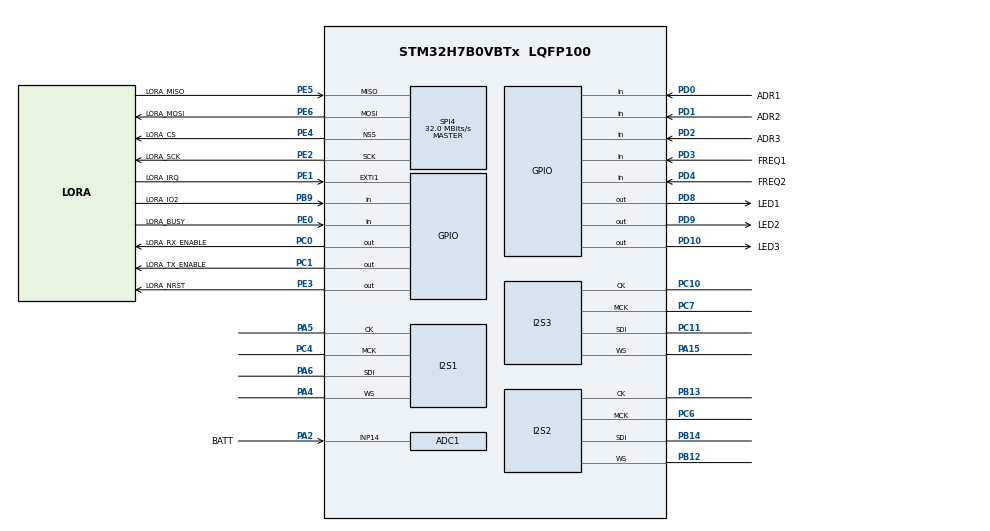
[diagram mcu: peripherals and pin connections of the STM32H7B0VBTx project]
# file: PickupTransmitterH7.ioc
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ADC1.Channel-0\#ChannelRegularConversion=ADC_CHANNEL_14
ADC1.NbrOfConversionFlag=1
ADC1.OffsetNumber-0\#ChannelRegularConversion=ADC_OFFSET_NONE
ADC1.OffsetSignedSaturation-0\#ChannelRegularConversion=DISABLE
ADC1.Rank-0\#ChannelRegularConversion=1
ADC1.SamplingTime-0\#ChannelRegularConversion=ADC_SAMPLETIME_1CYCLE_5
ADC1.master=1
CORTEX_M7.default_mode_Activation=1
Dma.Request0=SPI1_RX
Dma.Request1=SPI2_RX
Dma.Request2=SPI3_RX
Dma.SPI1_RX.0.Direction=DMA_PERIPH_TO_MEMORY
Dma.SPI1_RX.0.EventEnable=DISABLE
Dma.SPI1_RX.0.FIFOMode=DMA_FIFOMODE_DISABLE
Dma.SPI1_RX.0.Instance=DMA1_Stream0
Dma.SPI1_RX.0.MemDataAlignment=DMA_MDATAALIGN_BYTE
Dma.SPI1_RX.0.MemInc=DMA_MINC_ENABLE
Dma.SPI1_RX.0.Mode=DMA_CIRCULAR
Dma.SPI1_RX.0.PeriphDataAlignment=DMA_PDATAALIGN_BYTE
Dma.SPI1_RX.0.PeriphInc=DMA_PINC_DISABLE
Dma.SPI1_RX.0.Polarity=HAL_DMAMUX_REQ_GEN_RISING
Dma.SPI1_RX.0.Priority=DMA_PRIORITY_LOW
Dma.SPI1_RX.0.RequestNumber=1
Dma.SPI1_RX.0.SignalID=NONE
Dma.SPI1_RX.0.SyncEnable=DISABLE
Dma.SPI1_RX.0.SyncPolarity=HAL_DMAMUX_SYNC_NO_EVENT
Dma.SPI1_RX.0.SyncRequestNumber=1
Dma.SPI1_RX.0.SyncSignalID=NONE
Dma.SPI2_RX.1.Direction=DMA_PERIPH_TO_MEMORY
Dma.SPI2_RX.1.EventEnable=DISABLE
Dma.SPI2_RX.1.FIFOMode=DMA_FIFOMODE_DISABLE
Dma.SPI2_RX.1.Instance=DMA1_Stream1
Dma.SPI2_RX.1.MemDataAlignment=DMA_MDATAALIGN_BYTE
Dma.SPI2_RX.1.MemInc=DMA_MINC_ENABLE
Dma.SPI2_RX.1.Mode=DMA_CIRCULAR
Dma.SPI2_RX.1.PeriphDataAlignment=DMA_PDATAALIGN_BYTE
Dma.SPI2_RX.1.PeriphInc=DMA_PINC_DISABLE
Dma.SPI2_RX.1.Polarity=HAL_DMAMUX_REQ_GEN_RISING
Dma.SPI2_RX.1.Priority=DMA_PRIORITY_LOW
Dma.SPI2_RX.1.RequestNumber=1
Dma.SPI2_RX.1.SignalID=NONE
Dma.SPI2_RX.1.SyncEnable=DISABLE
Dma.SPI2_RX.1.SyncPolarity=HAL_DMAMUX_SYNC_NO_EVENT
Dma.SPI2_RX.1.SyncRequestNumber=1
Dma.SPI2_RX.1.SyncSignalID=NONE
Dma.SPI3_RX.2.Direction=DMA_PERIPH_TO_MEMORY
Dma.SPI3_RX.2.EventEnable=DISABLE
Dma.SPI3_RX.2.FIFOMode=DMA_FIFOMODE_DISABLE
Dma.SPI3_RX.2.Instance=DMA1_Stream2
Dma.SPI3_RX.2.MemDataAlignment=DMA_MDATAALIGN_BYTE
Dma.SPI3_RX.2.MemInc=DMA_MINC_ENABLE
Dma.SPI3_RX.2.Mode=DMA_CIRCULAR
Dma.SPI3_RX.2.PeriphDataAlignment=DMA_PDATAALIGN_BYTE
Dma.SPI3_RX.2.PeriphInc=DMA_PINC_DISABLE
Dma.SPI3_RX.2.Polarity=HAL_DMAMUX_REQ_GEN_RISING
Dma.SPI3_RX.2.Priority=DMA_PRIORITY_LOW
Dma.SPI3_RX.2.RequestNumber=1
Dma.SPI3_RX.2.SignalID=NONE
Dma.SPI3_RX.2.SyncEnable=DISABLE
Dma.SPI3_RX.2.SyncPolarity=HAL_DMAMUX_SYNC_NO_EVENT
Dma.SPI3_RX.2.SyncRequestNumber=1
Dma.SPI3_RX.2.SyncSignalID=NONE
I2S1.DataFormat=I2S_DATAFORMAT_24B
I2S1.ErrorAudioFreq=0.8 %
I2S1.Instance=SPI$Index
I2S1.RealAudioFreq=8.064 KHz
I2S2.DataFormat=I2S_DATAFORMAT_24B
I2S2.ErrorAudioFreq=0.8 %
I2S2.Instance=SPI$Index
I2S2.RealAudioFreq=8.064 KHz
I2S3.DataFormat=I2S_DATAFORMAT_24B
I2S3.ErrorAudioFreq=0.8 %
I2S3.Instance=SPI$Index
I2S3.RealAudioFreq=8.064 KHz
Mcu.Family=STM32H7
Mcu.Name=STM32H7B0VBTx
Mcu.Package=LQFP100
NVIC.DMA1_Stream0_IRQn=true\:0\:0\:false\:false\:true\:false\:true\:true
NVIC.DMA1_Stream1_IRQn=true\:0\:0\:false\:false\:true\:false\:true\:true
NVIC.DMA1_Stream2_IRQn=true\:0\:0\:false\:false\:true\:false\:true\:true
NVIC.PriorityGroup=NVIC_PRIORITYGROUP_4
PA13.Mode=Trace_Asynchronous_SW
PA13.Signal=DEBUG_JTMS-SWDIO
PA14.Mode=Trace_Asynchronous_SW
PA14.Signal=DEBUG_JTCK-SWCLK
PA15.Mode=Half_Duplex_Master_Rx
PA15.Signal=I2S3_WS
PA2.GPIO_Label=BATT
PA2.Signal=ADCx_INP14
PA4.Mode=Half_Duplex_Master_Rx
PA4.Signal=I2S1_WS
PA5.Mode=Half_Duplex_Master_Rx
PA5.Signal=I2S1_CK
PA6.Mode=Half_Duplex_Master_Rx
PA6.Signal=I2S1_SDI
PB12.Mode=Half_Duplex_Master_Rx
PB12.Signal=I2S2_WS
PB13.Mode=Half_Duplex_Master_Rx
PB13.Signal=I2S2_CK
PB14.Mode=Half_Duplex_Master_Rx
PB14.Signal=I2S2_SDI
PB3.Mode=Trace_Asynchronous_SW
PB3.Signal=DEBUG_JTDO-SWO
PB9.GPIO_Label=LORA_IO2
PB9.Signal=GPIO_Input
PC0.GPIO_Label=LORA_RX_ENABLE
PC0.Signal=GPIO_Output
PC1.GPIO_Label=LORA_TX_ENABLE
PC1.Signal=GPIO_Output
PC10.Mode=Half_Duplex_Master_Rx
PC10.Signal=I2S3_CK
PC11.Mode=Half_Duplex_Master_Rx
PC11.Signal=I2S3_SDI
PC14-OSC32_IN.Mode=LSE-External-Oscillator
PC14-OSC32_IN.Signal=RCC_OSC32_IN
PC15-OSC32_OUT.Mode=LSE-External-Oscillator
PC15-OSC32_OUT.Signal=RCC_OSC32_OUT
PC4.Mode=Master_Clock_Activated
PC4.Signal=I2S1_MCK
PC6.Mode=Master_Clock_Activated
PC6.Signal=I2S2_MCK
PC7.Mode=Master_Clock_Activated
PC7.Signal=I2S3_MCK
PD0.GPIO_Label=ADR1
PD0.Signal=GPIO_Input
PD1.GPIO_Label=ADR2
PD1.Signal=GPIO_Input
PD10.GPIO_Label=LED3
PD10.Signal=GPIO_Output
PD2.GPIO_Label=ADR3
PD2.Signal=GPIO_Input
PD3.GPIO_Label=FREQ1
PD3.Signal=GPIO_Input
PD4.GPIO_Label=FREQ2
PD4.Signal=GPIO_Input
PD8.GPIO_Label=LED1
PD8.Signal=GPIO_Output
PD9.GPIO_Label=LED2
PD9.Signal=GPIO_Output
PE0.GPIO_Label=LORA_BUSY
PE0.Signal=GPIO_Input
PE1.GPIO_Label=LORA_IRQ
PE1.Signal=GPXTI1
PE2.GPIO_Label=LORA_SCK
PE2.Mode=Full_Duplex_Master
PE2.Signal=SPI4_SCK
PE3.GPIO_Label=LORA_NRST
PE3.Signal=GPIO_Output
PE4.GPIO_Label=LORA_CS
PE4.Mode=NSS_Signal_Hard_Output
PE4.Signal=SPI4_NSS
PE5.GPIO_Label=LORA_MISO
PE5.Mode=Full_Duplex_Master
PE5.Signal=SPI4_MISO
PE6.GPIO_Label=LORA_MOSI
PE6.Mode=Full_Duplex_Master
PE6.Signal=SPI4_MOSI
PH0-OSC_IN.Mode=HSE-External-Oscillator
PH0-OSC_IN.Signal=RCC_OSC_IN
PH1-OSC_OUT.Mode=HSE-External-Oscillator
PH1-OSC_OUT.Signal=RCC_OSC_OUT
ProjectManager.HeapSize=0x200
ProjectManager.StackSize=0x400
ProjectManager.TargetToolchain=STM32CubeIDE
RCC.ADCFreq_Value=42666666.666666664
RCC.APB1Freq_Value=64000000
RCC.APB2Freq_Value=64000000
RCC.APB3Freq_Value=64000000
RCC.APB4Freq_Value=64000000
RCC.CortexFreq_Value=64000000
RCC.DIVM1=4
RCC.DIVM2=4
RCC.DIVN1=8
RCC.DIVN2=8
RCC.DIVP2=3
RCC.HCLKFreq_Value=64000000
RCC.HSE_VALUE=32000000
RCC.PLL2FRACN=0
RCC.PLL3FRACN=0
RCC.PLLFRACN=0
RCC.SYSCLKFreq_VALUE=64000000
RCC.SYSCLKSource=RCC_SYSCLKSOURCE_PLLCLK
RCC.USBFreq_Value=64000000
SH.ADCx_INP14.0=ADC1_INP14,IN14-Single-Ended
SPI4.CalculateBaudRate=32.0 MBits/s
SPI4.Direction=SPI_DIRECTION_2LINES
SPI4.Mode=SPI_MODE_MASTER
SPI4.VirtualNSS=VM_NSSHARD
SPI4.VirtualType=VM_MASTER
VP_MEMORYMAP_VS_MEMORYMAP.Mode=CurAppReg
board=custom

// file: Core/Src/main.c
/* USER CODE BEGIN Header */
/**
  ******************************************************************************
  * @file           : main.c
  * @brief          : Main program body
  ******************************************************************************
  * @attention
  *
  * Copyright (c) 2024 STMicroelectronics.
  * All rights reserved.
  *
  * This software is licensed under terms that can be found in the LICENSE file
  * in the root directory of this software component.
  * If no LICENSE file comes with this software, it is provided AS-IS.
  *
  ******************************************************************************
  */
/* USER CODE END Header */
#include "main.h"

/* USER CODE BEGIN Includes */
#include "AudioInputStream.h"

/* USER CODE END Includes */

ADC_HandleTypeDef hadc1;

I2S_HandleTypeDef hi2s1;
I2S_HandleTypeDef hi2s2;
I2S_HandleTypeDef hi2s3;
DMA_HandleTypeDef hdma_spi1_rx;
DMA_HandleTypeDef hdma_spi2_rx;
DMA_HandleTypeDef hdma_spi3_rx;

SPI_HandleTypeDef hspi4;

/* USER CODE BEGIN PV */

// input stream
input_stream_t iStream;

/* USER CODE END PV */

void SystemClock_Config(void);
static void MPU_Config(void);
static void MX_GPIO_Init(void);
static void MX_DMA_Init(void);
static void MX_I2S1_Init(void);
static void MX_I2S2_Init(void);
static void MX_I2S3_Init(void);
static void MX_SPI4_Init(void);
static void MX_ADC1_Init(void);

/* USER CODE BEGIN 0 */

//I2S callbacks-------------------------

void HAL_I2S_RxHalfCpltCallback (I2S_HandleTypeDef * i2s){
	rx_half_complete(iStream, i2s);
}

void HAL_I2S_RxCpltCallback (I2S_HandleTypeDef * i2s){
	rx_complete(iStream, i2s);
}

/* USER CODE END 0 */

int main(void)
{

  /* MPU Configuration--------------------------------------------------------*/
  MPU_Config();

  /* MCU Configuration--------------------------------------------------------*/

  /* Reset of all peripherals, Initializes the Flash interface and the Systick. */
  HAL_Init();

  /* Configure the system clock */
  SystemClock_Config();

  /* Initialize all configured peripherals */
  MX_GPIO_Init();
  MX_DMA_Init();
  MX_I2S1_Init();
  MX_I2S2_Init();
  MX_I2S3_Init();
  MX_SPI4_Init();
  MX_ADC1_Init();
  /* USER CODE BEGIN 2 */
  iStream = create_input_stream();
  input_stream_begin(iStream);

  /* USER CODE END 2 */

  /* Infinite loop */
  /* USER CODE BEGIN WHILE */
  while (1)
  {
	  input_stream_tick(iStream);
    /* USER CODE END WHILE */

  }
}

void SystemClock_Config(void)
{
  RCC_OscInitTypeDef RCC_OscInitStruct = {0};
  RCC_ClkInitTypeDef RCC_ClkInitStruct = {0};

  /*AXI clock gating */
  RCC->CKGAENR = 0xFFFFFFFF;

  /** Supply configuration update enable
  */
  HAL_PWREx_ConfigSupply(PWR_LDO_SUPPLY);

  /** Configure the main internal regulator output voltage
  */
  __HAL_PWR_VOLTAGESCALING_CONFIG(PWR_REGULATOR_VOLTAGE_SCALE3);

  while(!__HAL_PWR_GET_FLAG(PWR_FLAG_VOSRDY)) {}

  /** Initializes the RCC Oscillators according to the specified parameters
  * in the RCC_OscInitTypeDef structure.
  */
  RCC_OscInitStruct.OscillatorType = RCC_OSCILLATORTYPE_HSI;
  RCC_OscInitStruct.HSIState = RCC_HSI_DIV1;
  RCC_OscInitStruct.HSICalibrationValue = 64;
  RCC_OscInitStruct.PLL.PLLState = RCC_PLL_ON;
  RCC_OscInitStruct.PLL.PLLSource = RCC_PLLSOURCE_HSI;
  RCC_OscInitStruct.PLL.PLLM = 4;
  RCC_OscInitStruct.PLL.PLLN = 8;
  RCC_OscInitStruct.PLL.PLLP = 2;
  RCC_OscInitStruct.PLL.PLLQ = 2;
  RCC_OscInitStruct.PLL.PLLR = 2;
  RCC_OscInitStruct.PLL.PLLRGE = RCC_PLL1VCIRANGE_3;
  RCC_OscInitStruct.PLL.PLLVCOSEL = RCC_PLL1VCOWIDE;
  RCC_OscInitStruct.PLL.PLLFRACN = 0;
  if (HAL_RCC_OscConfig(&RCC_OscInitStruct) != HAL_OK)
  {
    Error_Handler();
  }

  /** Initializes the CPU, AHB and APB buses clocks
  */
  RCC_ClkInitStruct.ClockType = RCC_CLOCKTYPE_HCLK|RCC_CLOCKTYPE_SYSCLK
                              |RCC_CLOCKTYPE_PCLK1|RCC_CLOCKTYPE_PCLK2
                              |RCC_CLOCKTYPE_D3PCLK1|RCC_CLOCKTYPE_D1PCLK1;
  RCC_ClkInitStruct.SYSCLKSource = RCC_SYSCLKSOURCE_PLLCLK;
  RCC_ClkInitStruct.SYSCLKDivider = RCC_SYSCLK_DIV1;
  RCC_ClkInitStruct.AHBCLKDivider = RCC_HCLK_DIV1;
  RCC_ClkInitStruct.APB3CLKDivider = RCC_APB3_DIV1;
  RCC_ClkInitStruct.APB1CLKDivider = RCC_APB1_DIV1;
  RCC_ClkInitStruct.APB2CLKDivider = RCC_APB2_DIV1;
  RCC_ClkInitStruct.APB4CLKDivider = RCC_APB4_DIV1;

  if (HAL_RCC_ClockConfig(&RCC_ClkInitStruct, FLASH_LATENCY_2) != HAL_OK)
  {
    Error_Handler();
  }
}

static void MX_ADC1_Init(void)
{

  ADC_MultiModeTypeDef multimode = {0};
  ADC_ChannelConfTypeDef sConfig = {0};

  /** Common config
  */
  hadc1.Instance = ADC1;
  hadc1.Init.ClockPrescaler = ADC_CLOCK_ASYNC_DIV1;
  hadc1.Init.Resolution = ADC_RESOLUTION_16B;
  hadc1.Init.ScanConvMode = ADC_SCAN_DISABLE;
  hadc1.Init.EOCSelection = ADC_EOC_SINGLE_CONV;
  hadc1.Init.LowPowerAutoWait = DISABLE;
  hadc1.Init.ContinuousConvMode = DISABLE;
  hadc1.Init.NbrOfConversion = 1;
  hadc1.Init.DiscontinuousConvMode = DISABLE;
  hadc1.Init.ExternalTrigConv = ADC_SOFTWARE_START;
  hadc1.Init.ExternalTrigConvEdge = ADC_EXTERNALTRIGCONVEDGE_NONE;
  hadc1.Init.ConversionDataManagement = ADC_CONVERSIONDATA_DR;
  hadc1.Init.Overrun = ADC_OVR_DATA_PRESERVED;
  hadc1.Init.LeftBitShift = ADC_LEFTBITSHIFT_NONE;
  hadc1.Init.OversamplingMode = DISABLE;
  if (HAL_ADC_Init(&hadc1) != HAL_OK)
  {
    Error_Handler();
  }

  /** Configure the ADC multi-mode
  */
  multimode.Mode = ADC_MODE_INDEPENDENT;
  if (HAL_ADCEx_MultiModeConfigChannel(&hadc1, &multimode) != HAL_OK)
  {
    Error_Handler();
  }

  /** Configure Regular Channel
  */
  sConfig.Channel = ADC_CHANNEL_14;
  sConfig.Rank = ADC_REGULAR_RANK_1;
  sConfig.SamplingTime = ADC_SAMPLETIME_1CYCLE_5;
  sConfig.SingleDiff = ADC_SINGLE_ENDED;
  sConfig.OffsetNumber = ADC_OFFSET_NONE;
  sConfig.Offset = 0;
  sConfig.OffsetSignedSaturation = DISABLE;
  if (HAL_ADC_ConfigChannel(&hadc1, &sConfig) != HAL_OK)
  {
    Error_Handler();
  }

}

static void MX_I2S1_Init(void)
{

  hi2s1.Instance = SPI1;
  hi2s1.Init.Mode = I2S_MODE_MASTER_RX;
  hi2s1.Init.Standard = I2S_STANDARD_PHILIPS;
  hi2s1.Init.DataFormat = I2S_DATAFORMAT_24B;
  hi2s1.Init.MCLKOutput = I2S_MCLKOUTPUT_ENABLE;
  hi2s1.Init.AudioFreq = I2S_AUDIOFREQ_8K;
  hi2s1.Init.CPOL = I2S_CPOL_LOW;
  hi2s1.Init.FirstBit = I2S_FIRSTBIT_MSB;
  hi2s1.Init.WSInversion = I2S_WS_INVERSION_DISABLE;
  hi2s1.Init.Data24BitAlignment = I2S_DATA_24BIT_ALIGNMENT_RIGHT;
  hi2s1.Init.MasterKeepIOState = I2S_MASTER_KEEP_IO_STATE_DISABLE;
  if (HAL_I2S_Init(&hi2s1) != HAL_OK)
  {
    Error_Handler();
  }

}

static void MX_I2S2_Init(void)
{

  hi2s2.Instance = SPI2;
  hi2s2.Init.Mode = I2S_MODE_MASTER_RX;
  hi2s2.Init.Standard = I2S_STANDARD_PHILIPS;
  hi2s2.Init.DataFormat = I2S_DATAFORMAT_24B;
  hi2s2.Init.MCLKOutput = I2S_MCLKOUTPUT_ENABLE;
  hi2s2.Init.AudioFreq = I2S_AUDIOFREQ_8K;
  hi2s2.Init.CPOL = I2S_CPOL_LOW;
  hi2s2.Init.FirstBit = I2S_FIRSTBIT_MSB;
  hi2s2.Init.WSInversion = I2S_WS_INVERSION_DISABLE;
  hi2s2.Init.Data24BitAlignment = I2S_DATA_24BIT_ALIGNMENT_RIGHT;
  hi2s2.Init.MasterKeepIOState = I2S_MASTER_KEEP_IO_STATE_DISABLE;
  if (HAL_I2S_Init(&hi2s2) != HAL_OK)
  {
    Error_Handler();
  }

}

static void MX_I2S3_Init(void)
{

  hi2s3.Instance = SPI3;
  hi2s3.Init.Mode = I2S_MODE_MASTER_RX;
  hi2s3.Init.Standard = I2S_STANDARD_PHILIPS;
  hi2s3.Init.DataFormat = I2S_DATAFORMAT_24B;
  hi2s3.Init.MCLKOutput = I2S_MCLKOUTPUT_ENABLE;
  hi2s3.Init.AudioFreq = I2S_AUDIOFREQ_8K;
  hi2s3.Init.CPOL = I2S_CPOL_LOW;
  hi2s3.Init.FirstBit = I2S_FIRSTBIT_MSB;
  hi2s3.Init.WSInversion = I2S_WS_INVERSION_DISABLE;
  hi2s3.Init.Data24BitAlignment = I2S_DATA_24BIT_ALIGNMENT_RIGHT;
  hi2s3.Init.MasterKeepIOState = I2S_MASTER_KEEP_IO_STATE_DISABLE;
  if (HAL_I2S_Init(&hi2s3) != HAL_OK)
  {
    Error_Handler();
  }

}

static void MX_SPI4_Init(void)
{

  /* SPI4 parameter configuration*/
  hspi4.Instance = SPI4;
  hspi4.Init.Mode = SPI_MODE_MASTER;
  hspi4.Init.Direction = SPI_DIRECTION_2LINES;
  hspi4.Init.DataSize = SPI_DATASIZE_4BIT;
  hspi4.Init.CLKPolarity = SPI_POLARITY_LOW;
  hspi4.Init.CLKPhase = SPI_PHASE_1EDGE;
  hspi4.Init.NSS = SPI_NSS_HARD_OUTPUT;
  hspi4.Init.BaudRatePrescaler = SPI_BAUDRATEPRESCALER_2;
  hspi4.Init.FirstBit = SPI_FIRSTBIT_MSB;
  hspi4.Init.TIMode = SPI_TIMODE_DISABLE;
  hspi4.Init.CRCCalculation = SPI_CRCCALCULATION_DISABLE;
  hspi4.Init.CRCPolynomial = 0x0;
  hspi4.Init.NSSPMode = SPI_NSS_PULSE_ENABLE;
  hspi4.Init.NSSPolarity = SPI_NSS_POLARITY_LOW;
  hspi4.Init.FifoThreshold = SPI_FIFO_THRESHOLD_01DATA;
  hspi4.Init.TxCRCInitializationPattern = SPI_CRC_INITIALIZATION_ALL_ZERO_PATTERN;
  hspi4.Init.RxCRCInitializationPattern = SPI_CRC_INITIALIZATION_ALL_ZERO_PATTERN;
  hspi4.Init.MasterSSIdleness = SPI_MASTER_SS_IDLENESS_00CYCLE;
  hspi4.Init.MasterInterDataIdleness = SPI_MASTER_INTERDATA_IDLENESS_00CYCLE;
  hspi4.Init.MasterReceiverAutoSusp = SPI_MASTER_RX_AUTOSUSP_DISABLE;
  hspi4.Init.MasterKeepIOState = SPI_MASTER_KEEP_IO_STATE_DISABLE;
  hspi4.Init.IOSwap = SPI_IO_SWAP_DISABLE;
  if (HAL_SPI_Init(&hspi4) != HAL_OK)
  {
    Error_Handler();
  }

}

static void MX_DMA_Init(void)
{

  /* DMA controller clock enable */
  __HAL_RCC_DMA1_CLK_ENABLE();

  /* DMA interrupt init */
  /* DMA1_Stream0_IRQn interrupt configuration */
  HAL_NVIC_SetPriority(DMA1_Stream0_IRQn, 0, 0);
  HAL_NVIC_EnableIRQ(DMA1_Stream0_IRQn);
  /* DMA1_Stream1_IRQn interrupt configuration */
  HAL_NVIC_SetPriority(DMA1_Stream1_IRQn, 0, 0);
  HAL_NVIC_EnableIRQ(DMA1_Stream1_IRQn);
  /* DMA1_Stream2_IRQn interrupt configuration */
  HAL_NVIC_SetPriority(DMA1_Stream2_IRQn, 0, 0);
  HAL_NVIC_EnableIRQ(DMA1_Stream2_IRQn);

}

static void MX_GPIO_Init(void)
{
  GPIO_InitTypeDef GPIO_InitStruct = {0};

  /* GPIO Ports Clock Enable */
  __HAL_RCC_GPIOE_CLK_ENABLE();
  __HAL_RCC_GPIOC_CLK_ENABLE();
  __HAL_RCC_GPIOH_CLK_ENABLE();
  __HAL_RCC_GPIOA_CLK_ENABLE();
  __HAL_RCC_GPIOB_CLK_ENABLE();
  __HAL_RCC_GPIOD_CLK_ENABLE();

  /*Configure GPIO pin Output Level */
  HAL_GPIO_WritePin(LORA_NRST_GPIO_Port, LORA_NRST_Pin, GPIO_PIN_RESET);

  /*Configure GPIO pin Output Level */
  HAL_GPIO_WritePin(GPIOC, LORA_RX_ENABLE_Pin|LORA_TX_ENABLE_Pin, GPIO_PIN_RESET);

  /*Configure GPIO pin Output Level */
  HAL_GPIO_WritePin(GPIOD, LED1_Pin|LED2_Pin|LED3_Pin, GPIO_PIN_RESET);

  /*Configure GPIO pin : LORA_NRST_Pin */
  GPIO_InitStruct.Pin = LORA_NRST_Pin;
  GPIO_InitStruct.Mode = GPIO_MODE_OUTPUT_PP;
  GPIO_InitStruct.Pull = GPIO_NOPULL;
  GPIO_InitStruct.Speed = GPIO_SPEED_FREQ_LOW;
  HAL_GPIO_Init(LORA_NRST_GPIO_Port, &GPIO_InitStruct);

  /*Configure GPIO pins : LORA_RX_ENABLE_Pin LORA_TX_ENABLE_Pin */
  GPIO_InitStruct.Pin = LORA_RX_ENABLE_Pin|LORA_TX_ENABLE_Pin;
  GPIO_InitStruct.Mode = GPIO_MODE_OUTPUT_PP;
  GPIO_InitStruct.Pull = GPIO_NOPULL;
  GPIO_InitStruct.Speed = GPIO_SPEED_FREQ_LOW;
  HAL_GPIO_Init(GPIOC, &GPIO_InitStruct);

  /*Configure GPIO pins : LED1_Pin LED2_Pin LED3_Pin */
  GPIO_InitStruct.Pin = LED1_Pin|LED2_Pin|LED3_Pin;
  GPIO_InitStruct.Mode = GPIO_MODE_OUTPUT_PP;
  GPIO_InitStruct.Pull = GPIO_NOPULL;
  GPIO_InitStruct.Speed = GPIO_SPEED_FREQ_LOW;
  HAL_GPIO_Init(GPIOD, &GPIO_InitStruct);

  /*Configure GPIO pins : ADR1_Pin ADR2_Pin ADR3_Pin FREQ1_Pin
                           FREQ2_Pin */
  GPIO_InitStruct.Pin = ADR1_Pin|ADR2_Pin|ADR3_Pin|FREQ1_Pin
                          |FREQ2_Pin;
  GPIO_InitStruct.Mode = GPIO_MODE_INPUT;
  GPIO_InitStruct.Pull = GPIO_NOPULL;
  HAL_GPIO_Init(GPIOD, &GPIO_InitStruct);

  /*Configure GPIO pin : LORA_IO2_Pin */
  GPIO_InitStruct.Pin = LORA_IO2_Pin;
  GPIO_InitStruct.Mode = GPIO_MODE_INPUT;
  GPIO_InitStruct.Pull = GPIO_NOPULL;
  HAL_GPIO_Init(LORA_IO2_GPIO_Port, &GPIO_InitStruct);

  /*Configure GPIO pin : LORA_BUSY_Pin */
  GPIO_InitStruct.Pin = LORA_BUSY_Pin;
  GPIO_InitStruct.Mode = GPIO_MODE_INPUT;
  GPIO_InitStruct.Pull = GPIO_NOPULL;
  HAL_GPIO_Init(LORA_BUSY_GPIO_Port, &GPIO_InitStruct);

  /*Configure GPIO pin : LORA_IRQ_Pin */
  GPIO_InitStruct.Pin = LORA_IRQ_Pin;
  GPIO_InitStruct.Mode = GPIO_MODE_IT_RISING;
  GPIO_InitStruct.Pull = GPIO_NOPULL;
  HAL_GPIO_Init(LORA_IRQ_GPIO_Port, &GPIO_InitStruct);

}

 /* MPU Configuration */

void MPU_Config(void)
{
  MPU_Region_InitTypeDef MPU_InitStruct = {0};

  /* Disables the MPU */
  HAL_MPU_Disable();

  /** Initializes and configures the Region and the memory to be protected
  */
  MPU_InitStruct.Enable = MPU_REGION_ENABLE;
  MPU_InitStruct.Number = MPU_REGION_NUMBER0;
  MPU_InitStruct.BaseAddress = 0x0;
  MPU_InitStruct.Size = MPU_REGION_SIZE_4GB;
  MPU_InitStruct.SubRegionDisable = 0x87;
  MPU_InitStruct.TypeExtField = MPU_TEX_LEVEL0;
  MPU_InitStruct.AccessPermission = MPU_REGION_NO_ACCESS;
  MPU_InitStruct.DisableExec = MPU_INSTRUCTION_ACCESS_DISABLE;
  MPU_InitStruct.IsShareable = MPU_ACCESS_SHAREABLE;
  MPU_InitStruct.IsCacheable = MPU_ACCESS_NOT_CACHEABLE;
  MPU_InitStruct.IsBufferable = MPU_ACCESS_NOT_BUFFERABLE;

  HAL_MPU_ConfigRegion(&MPU_InitStruct);
  /* Enables the MPU */
  HAL_MPU_Enable(MPU_PRIVILEGED_DEFAULT);

}

void Error_Handler(void)
{
  __disable_irq();
  while (1)
  {
  }
}
